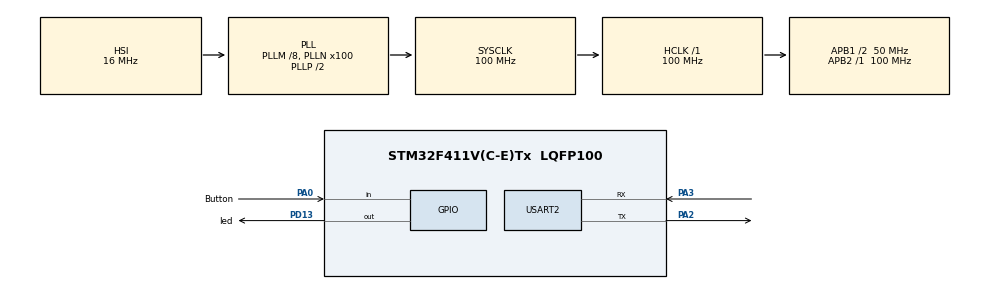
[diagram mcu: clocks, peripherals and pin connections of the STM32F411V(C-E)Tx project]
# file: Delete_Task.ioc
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FREERTOS.Tasks01=Task1,0,500,Task_led_handle,Default,NULL,Dynamic,NULL,NULL;Task2,2,500,Task_button_handle,Default,NULL,Dynamic,NULL,NULL
Mcu.Family=STM32F4
Mcu.Name=STM32F411V(C-E)Tx
Mcu.Package=LQFP100
NVIC.PriorityGroup=NVIC_PRIORITYGROUP_4
NVIC.TIM4_IRQn=true\:0\:0\:false\:false\:true\:false\:false\:true
NVIC.TimeBase=TIM4_IRQn
NVIC.TimeBaseIP=TIM4
PA0-WKUP.GPIO_Label=Button
PA0-WKUP.Signal=GPIO_Input
PA13.Mode=Serial_Wire
PA13.Signal=SYS_JTMS-SWDIO
PA14.Mode=Serial_Wire
PA14.Signal=SYS_JTCK-SWCLK
PA2.Mode=Asynchronous
PA2.Signal=USART2_TX
PA3.Mode=Asynchronous
PA3.Signal=USART2_RX
PD13.GPIO_Label=led
PD13.Signal=GPIO_Output
PH0\ -\ OSC_IN.Mode=HSE-External-Oscillator
PH0\ -\ OSC_IN.Signal=RCC_OSC_IN
PH1\ -\ OSC_OUT.Mode=HSE-External-Oscillator
PH1\ -\ OSC_OUT.Signal=RCC_OSC_OUT
ProjectManager.HeapSize=0x200
ProjectManager.StackSize=0x400
ProjectManager.TargetToolchain=MDK-ARM V5.27
RCC.48MHZClocksFreq_Value=50000000
RCC.AHBFreq_Value=100000000
RCC.APB1CLKDivider=RCC_HCLK_DIV2
RCC.APB1Freq_Value=50000000
RCC.APB1TimFreq_Value=100000000
RCC.APB2Freq_Value=100000000
RCC.APB2TimFreq_Value=100000000
RCC.CortexFreq_Value=100000000
RCC.HCLKFreq_Value=100000000
RCC.HSE_VALUE=25000000
RCC.HSI_VALUE=16000000
RCC.LSE_VALUE=32768
RCC.PLLM=8
RCC.PLLN=100
RCC.SYSCLKFreq_VALUE=100000000
RCC.SYSCLKSource=RCC_SYSCLKSOURCE_PLLCLK
RCC.VCOOutputFreq_Value=200000000
USART2.VirtualMode=VM_ASYNC
VP_FREERTOS_VS_CMSIS_V1.Mode=CMSIS_V1
VP_SYS_VS_tim4.Mode=TIM4
board=custom

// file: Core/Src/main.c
/* USER CODE BEGIN Header */
/**
  ******************************************************************************
  * @file           : main.c
  * @brief          : Main program body
  ******************************************************************************
  * @attention
  *
  * <h2><center>&copy; Copyright (c) 2021 STMicroelectronics.
  * All rights reserved.</center></h2>
  *
  * This software component is licensed by ST under Ultimate Liberty license
  * SLA0044, the "License"; You may not use this file except in compliance with
  * the License. You may obtain a copy of the License at:
  *                             www.st.com/SLA0044
  *
  ******************************************************************************
  */
/* USER CODE END Header */
#include "main.h"
#include "cmsis_os.h"

UART_HandleTypeDef huart2;

osThreadId Task1Handle;
osThreadId Task2Handle;

void SystemClock_Config(void);
static void MX_GPIO_Init(void);
static void MX_USART2_UART_Init(void);
void Task_led_handle(void const * argument);
void Task_button_handle(void const * argument);

/* USER CODE BEGIN 0 */
void Send_message(char *Mes)
	{
		HAL_UART_Transmit(&huart2,(uint8_t*)Mes,30,500);
	}
/* USER CODE END 0 */

int main(void)
{

  /* MCU Configuration--------------------------------------------------------*/

  /* Reset of all peripherals, Initializes the Flash interface and the Systick. */
  HAL_Init();

  /* Configure the system clock */
  SystemClock_Config();

  /* Initialize all configured peripherals */
  MX_GPIO_Init();
  MX_USART2_UART_Init();
  /* USER CODE BEGIN 2 */
char  start[]="This is delete task demo\r\n";
 HAL_UART_Transmit(&huart2,(uint8_t*)start,sizeof(start),500);
  /* USER CODE END 2 */

  /* Create the thread(s) */
  /* definition and creation of Task1 */
  osThreadDef(Task1, Task_led_handle, osPriorityNormal, 0, 500);
  Task1Handle = osThreadCreate(osThread(Task1), NULL);

  /* definition and creation of Task2 */
  osThreadDef(Task2, Task_button_handle, osPriorityHigh, 0, 500);
  Task2Handle = osThreadCreate(osThread(Task2), NULL);

  /* Start scheduler */
  osKernelStart();

  /* We should never get here as control is now taken by the scheduler */
  /* Infinite loop */
  while (1)
  {

  }
}

void SystemClock_Config(void)
{
  RCC_OscInitTypeDef RCC_OscInitStruct = {0};
  RCC_ClkInitTypeDef RCC_ClkInitStruct = {0};

  /** Configure the main internal regulator output voltage
  */
  __HAL_RCC_PWR_CLK_ENABLE();
  __HAL_PWR_VOLTAGESCALING_CONFIG(PWR_REGULATOR_VOLTAGE_SCALE1);
  /** Initializes the RCC Oscillators according to the specified parameters
  * in the RCC_OscInitTypeDef structure.
  */
  RCC_OscInitStruct.OscillatorType = RCC_OSCILLATORTYPE_HSI;
  RCC_OscInitStruct.HSIState = RCC_HSI_ON;
  RCC_OscInitStruct.HSICalibrationValue = RCC_HSICALIBRATION_DEFAULT;
  RCC_OscInitStruct.PLL.PLLState = RCC_PLL_ON;
  RCC_OscInitStruct.PLL.PLLSource = RCC_PLLSOURCE_HSI;
  RCC_OscInitStruct.PLL.PLLM = 8;
  RCC_OscInitStruct.PLL.PLLN = 100;
  RCC_OscInitStruct.PLL.PLLP = RCC_PLLP_DIV2;
  RCC_OscInitStruct.PLL.PLLQ = 4;
  if (HAL_RCC_OscConfig(&RCC_OscInitStruct) != HAL_OK)
  {
    Error_Handler();
  }
  /** Initializes the CPU, AHB and APB buses clocks
  */
  RCC_ClkInitStruct.ClockType = RCC_CLOCKTYPE_HCLK|RCC_CLOCKTYPE_SYSCLK
                              |RCC_CLOCKTYPE_PCLK1|RCC_CLOCKTYPE_PCLK2;
  RCC_ClkInitStruct.SYSCLKSource = RCC_SYSCLKSOURCE_PLLCLK;
  RCC_ClkInitStruct.AHBCLKDivider = RCC_SYSCLK_DIV1;
  RCC_ClkInitStruct.APB1CLKDivider = RCC_HCLK_DIV2;
  RCC_ClkInitStruct.APB2CLKDivider = RCC_HCLK_DIV1;

  if (HAL_RCC_ClockConfig(&RCC_ClkInitStruct, FLASH_LATENCY_3) != HAL_OK)
  {
    Error_Handler();
  }
}

static void MX_USART2_UART_Init(void)
{

  huart2.Instance = USART2;
  huart2.Init.BaudRate = 115200;
  huart2.Init.WordLength = UART_WORDLENGTH_8B;
  huart2.Init.StopBits = UART_STOPBITS_1;
  huart2.Init.Parity = UART_PARITY_NONE;
  huart2.Init.Mode = UART_MODE_TX_RX;
  huart2.Init.HwFlowCtl = UART_HWCONTROL_NONE;
  huart2.Init.OverSampling = UART_OVERSAMPLING_16;
  if (HAL_UART_Init(&huart2) != HAL_OK)
  {
    Error_Handler();
  }

}

static void MX_GPIO_Init(void)
{
  GPIO_InitTypeDef GPIO_InitStruct = {0};

  /* GPIO Ports Clock Enable */
  __HAL_RCC_GPIOH_CLK_ENABLE();
  __HAL_RCC_GPIOA_CLK_ENABLE();
  __HAL_RCC_GPIOD_CLK_ENABLE();

  /*Configure GPIO pin Output Level */
  HAL_GPIO_WritePin(led_GPIO_Port, led_Pin, GPIO_PIN_RESET);

  /*Configure GPIO pin : Button_Pin */
  GPIO_InitStruct.Pin = Button_Pin;
  GPIO_InitStruct.Mode = GPIO_MODE_INPUT;
  GPIO_InitStruct.Pull = GPIO_NOPULL;
  HAL_GPIO_Init(Button_GPIO_Port, &GPIO_InitStruct);

  /*Configure GPIO pin : led_Pin */
  GPIO_InitStruct.Pin = led_Pin;
  GPIO_InitStruct.Mode = GPIO_MODE_OUTPUT_PP;
  GPIO_InitStruct.Pull = GPIO_NOPULL;
  GPIO_InitStruct.Speed = GPIO_SPEED_FREQ_LOW;
  HAL_GPIO_Init(led_GPIO_Port, &GPIO_InitStruct);

}

void Task_led_handle(void const * argument)
{
  /* USER CODE BEGIN 5 */
	Send_message("led_Task is running\n");
  /* Infinite loop */
  for(;;)
  {
    osDelay(200);
		HAL_GPIO_TogglePin(GPIOD,GPIO_PIN_13);
  }
  /* USER CODE END 5 */
}

void Task_button_handle(void const * argument)
{
  /* USER CODE BEGIN Task_button_handle */
  /* Infinite loop */
	Send_message("button_task is runing\r\n");

  for(;;)
  {
		if(HAL_GPIO_ReadPin(GPIOA,GPIO_PIN_0)==0)
			{
				// if button not pressed on the dis board
				HAL_GPIO_WritePin(GPIOD,GPIO_PIN_13,GPIO_PIN_SET);
			}else
			{
				Send_message("button_task is deleted\r\n ");
				vTaskDelete(NULL);
			}

  }
  /* USER CODE END Task_button_handle */
}

 /**
  * @brief  Period elapsed callback in non blocking mode
  * @note   This function is called  when TIM4 interrupt took place, inside
  * HAL_TIM_IRQHandler(). It makes a direct call to HAL_IncTick() to increment
  * a global variable "uwTick" used as application time base.
  * @param  htim : TIM handle
  * @retval None
  */
void HAL_TIM_PeriodElapsedCallback(TIM_HandleTypeDef *htim)
{
  if (htim->Instance == TIM4) {
    HAL_IncTick();
  }
}

void Error_Handler(void)
{
  __disable_irq();
  while (1)
  {
  }
}

/************************ (C) COPYRIGHT STMicroelectronics *****END OF FILE****/
